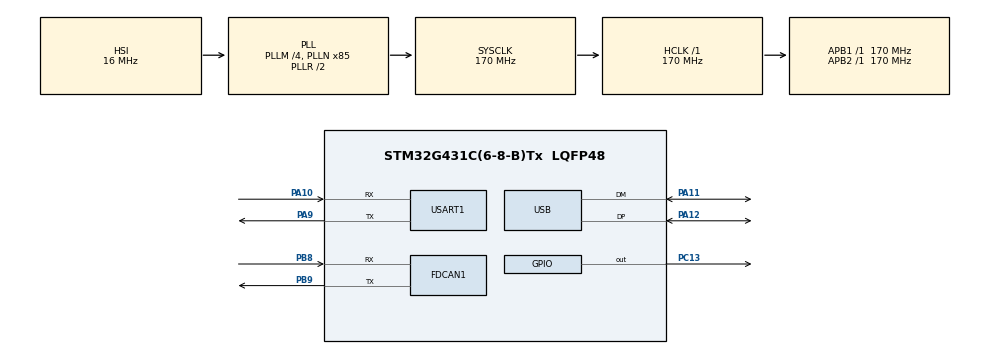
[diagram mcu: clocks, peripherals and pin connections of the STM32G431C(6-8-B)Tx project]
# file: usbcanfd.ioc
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FDCAN1.CalculateBaudRateNominal=499999
FDCAN1.CalculateTimeBitNominal=2000
FDCAN1.CalculateTimeQuantumNominal=117.64705882352942
FDCAN1.DataPrescaler=5
FDCAN1.DataTimeSeg1=14
FDCAN1.DataTimeSeg2=2
FDCAN1.FrameFormat=FDCAN_FRAME_FD_BRS
FDCAN1.NominalPrescaler=20
FDCAN1.NominalTimeSeg1=14
FDCAN1.NominalTimeSeg2=2
Mcu.Family=STM32G4
Mcu.Name=STM32G431C(6-8-B)Tx
Mcu.Package=LQFP48
NVIC.FDCAN1_IT0_IRQn=true\:0\:0\:false\:false\:true\:true\:true\:true
NVIC.FDCAN1_IT1_IRQn=true\:0\:0\:false\:false\:true\:true\:true\:true
NVIC.PriorityGroup=NVIC_PRIORITYGROUP_4
NVIC.USB_LP_IRQn=true\:0\:0\:false\:false\:true\:false\:true\:true
PA10.Mode=Asynchronous
PA10.Signal=USART1_RX
PA11.Mode=Device
PA11.Signal=USB_DM
PA12.Mode=Device
PA12.Signal=USB_DP
PA9.Mode=Asynchronous
PA9.Signal=USART1_TX
PB8-BOOT0.Mode=FDCAN_Activate
PB8-BOOT0.Signal=FDCAN1_RX
PB9.Mode=FDCAN_Activate
PB9.Signal=FDCAN1_TX
PC13.PinState=GPIO_PIN_SET
PC13.Signal=GPIO_Output
PF0-OSC_IN.Mode=HSE-External-Oscillator
PF0-OSC_IN.Signal=RCC_OSC_IN
PF1-OSC_OUT.Mode=HSE-External-Oscillator
PF1-OSC_OUT.Signal=RCC_OSC_OUT
ProjectManager.HeapSize=0x200
ProjectManager.StackSize=0x400
ProjectManager.TargetToolchain=STM32CubeIDE
RCC.ADC12Freq_Value=170000000
RCC.AHBFreq_Value=170000000
RCC.APB1Freq_Value=170000000
RCC.APB1TimFreq_Value=170000000
RCC.APB2Freq_Value=170000000
RCC.APB2TimFreq_Value=170000000
RCC.CK48CLockSelection=RCC_USBCLKSOURCE_HSI48
RCC.CortexFreq_Value=170000000
RCC.EXTERNAL_CLOCK_VALUE=12288000
RCC.HCLKFreq_Value=170000000
RCC.HSE_VALUE=8000000
RCC.HSI48_VALUE=48000000
RCC.HSI_VALUE=16000000
RCC.LSE_VALUE=32768
RCC.PLLM=RCC_PLLM_DIV4
RCC.PLLN=85
RCC.SYSCLKFreq_VALUE=170000000
RCC.SYSCLKSource=RCC_SYSCLKSOURCE_PLLCLK
RCC.USART1CLockSelection=RCC_USART1CLKSOURCE_HSI
RCC.USBFreq_Value=48000000
RCC.VCOOutputFreq_Value=340000000
USART1.VirtualMode-Asynchronous=VM_ASYNC
USB_DEVICE.CLASS_NAME_FS=CDC
USB_DEVICE.VirtualMode=Cdc
USB_DEVICE.VirtualModeFS=Cdc_FS
VP_SYS_VS_DBSignals.Mode=DisableDeadBatterySignals
VP_USB_DEVICE_VS_USB_DEVICE_CDC_FS.Mode=CDC_FS
board=custom

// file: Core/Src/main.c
/* USER CODE BEGIN Header */
/**
  ******************************************************************************
  * @file           : main.c
  * @brief          : Main program body
  ******************************************************************************
  * @attention
  *
  * Copyright (c) 2025 STMicroelectronics.
  * All rights reserved.
  *
  * This software is licensed under terms that can be found in the LICENSE file
  * in the root directory of this software component.
  * If no LICENSE file comes with this software, it is provided AS-IS.
  *
  ******************************************************************************
  */
/* USER CODE END Header */
#include "main.h"
#include "usb_device.h"

/* USER CODE BEGIN Includes */
#include "log.h"
#include "hsl.h"
#include "can.h"
/* USER CODE END Includes */

FDCAN_HandleTypeDef hfdcan1;

UART_HandleTypeDef huart1;

void SystemClock_Config(void);
static void MX_GPIO_Init(void);
static void MX_FDCAN1_Init(void);
static void MX_USART1_UART_Init(void);

int main(void)
{

  /* MCU Configuration--------------------------------------------------------*/

  /* Reset of all peripherals, Initializes the Flash interface and the Systick. */
  HAL_Init();

  /* Configure the system clock */
  SystemClock_Config();

  /* Initialize all configured peripherals */
  MX_GPIO_Init();
  MX_FDCAN1_Init();
  MX_USART1_UART_Init();
  MX_USB_Device_Init();
  /* USER CODE BEGIN 2 */

  log_init();
  hsl_init();

  /* USER CODE END 2 */

  /* Infinite loop */
  /* USER CODE BEGIN WHILE */
  while (1)
  {
    log_process();
    hsl_process();
    can_process();
    /* USER CODE END WHILE */

  }
}

void SystemClock_Config(void)
{
  RCC_OscInitTypeDef RCC_OscInitStruct = {0};
  RCC_ClkInitTypeDef RCC_ClkInitStruct = {0};

  /** Configure the main internal regulator output voltage
  */
  HAL_PWREx_ControlVoltageScaling(PWR_REGULATOR_VOLTAGE_SCALE1_BOOST);

  /** Initializes the RCC Oscillators according to the specified parameters
  * in the RCC_OscInitTypeDef structure.
  */
  RCC_OscInitStruct.OscillatorType = RCC_OSCILLATORTYPE_HSI|RCC_OSCILLATORTYPE_HSI48;
  RCC_OscInitStruct.HSIState = RCC_HSI_ON;
  RCC_OscInitStruct.HSICalibrationValue = RCC_HSICALIBRATION_DEFAULT;
  RCC_OscInitStruct.HSI48State = RCC_HSI48_ON;
  RCC_OscInitStruct.PLL.PLLState = RCC_PLL_ON;
  RCC_OscInitStruct.PLL.PLLSource = RCC_PLLSOURCE_HSI;
  RCC_OscInitStruct.PLL.PLLM = RCC_PLLM_DIV4;
  RCC_OscInitStruct.PLL.PLLN = 85;
  RCC_OscInitStruct.PLL.PLLP = RCC_PLLP_DIV2;
  RCC_OscInitStruct.PLL.PLLQ = RCC_PLLQ_DIV2;
  RCC_OscInitStruct.PLL.PLLR = RCC_PLLR_DIV2;
  if (HAL_RCC_OscConfig(&RCC_OscInitStruct) != HAL_OK)
  {
    Error_Handler();
  }

  /** Initializes the CPU, AHB and APB buses clocks
  */
  RCC_ClkInitStruct.ClockType = RCC_CLOCKTYPE_HCLK|RCC_CLOCKTYPE_SYSCLK
                              |RCC_CLOCKTYPE_PCLK1|RCC_CLOCKTYPE_PCLK2;
  RCC_ClkInitStruct.SYSCLKSource = RCC_SYSCLKSOURCE_PLLCLK;
  RCC_ClkInitStruct.AHBCLKDivider = RCC_SYSCLK_DIV1;
  RCC_ClkInitStruct.APB1CLKDivider = RCC_HCLK_DIV1;
  RCC_ClkInitStruct.APB2CLKDivider = RCC_HCLK_DIV1;

  if (HAL_RCC_ClockConfig(&RCC_ClkInitStruct, FLASH_LATENCY_4) != HAL_OK)
  {
    Error_Handler();
  }
}

static void MX_FDCAN1_Init(void)
{

  hfdcan1.Instance = FDCAN1;
  hfdcan1.Init.ClockDivider = FDCAN_CLOCK_DIV1;
  hfdcan1.Init.FrameFormat = FDCAN_FRAME_FD_BRS;
  hfdcan1.Init.Mode = FDCAN_MODE_NORMAL;
  hfdcan1.Init.AutoRetransmission = DISABLE;
  hfdcan1.Init.TransmitPause = DISABLE;
  hfdcan1.Init.ProtocolException = DISABLE;
  hfdcan1.Init.NominalPrescaler = 20;
  hfdcan1.Init.NominalSyncJumpWidth = 1;
  hfdcan1.Init.NominalTimeSeg1 = 14;
  hfdcan1.Init.NominalTimeSeg2 = 2;
  hfdcan1.Init.DataPrescaler = 5;
  hfdcan1.Init.DataSyncJumpWidth = 1;
  hfdcan1.Init.DataTimeSeg1 = 14;
  hfdcan1.Init.DataTimeSeg2 = 2;
  hfdcan1.Init.StdFiltersNbr = 0;
  hfdcan1.Init.ExtFiltersNbr = 0;
  hfdcan1.Init.TxFifoQueueMode = FDCAN_TX_FIFO_OPERATION;
  if (HAL_FDCAN_Init(&hfdcan1) != HAL_OK)
  {
    Error_Handler();
  }

}

static void MX_USART1_UART_Init(void)
{

  huart1.Instance = USART1;
  huart1.Init.BaudRate = 115200;
  huart1.Init.WordLength = UART_WORDLENGTH_8B;
  huart1.Init.StopBits = UART_STOPBITS_1;
  huart1.Init.Parity = UART_PARITY_NONE;
  huart1.Init.Mode = UART_MODE_TX_RX;
  huart1.Init.HwFlowCtl = UART_HWCONTROL_NONE;
  huart1.Init.OverSampling = UART_OVERSAMPLING_16;
  huart1.Init.OneBitSampling = UART_ONE_BIT_SAMPLE_DISABLE;
  huart1.Init.ClockPrescaler = UART_PRESCALER_DIV1;
  huart1.AdvancedInit.AdvFeatureInit = UART_ADVFEATURE_NO_INIT;
  if (HAL_UART_Init(&huart1) != HAL_OK)
  {
    Error_Handler();
  }
  if (HAL_UARTEx_SetTxFifoThreshold(&huart1, UART_TXFIFO_THRESHOLD_1_8) != HAL_OK)
  {
    Error_Handler();
  }
  if (HAL_UARTEx_SetRxFifoThreshold(&huart1, UART_RXFIFO_THRESHOLD_1_8) != HAL_OK)
  {
    Error_Handler();
  }
  if (HAL_UARTEx_DisableFifoMode(&huart1) != HAL_OK)
  {
    Error_Handler();
  }

}

static void MX_GPIO_Init(void)
{
  GPIO_InitTypeDef GPIO_InitStruct = {0};

  /* GPIO Ports Clock Enable */
  __HAL_RCC_GPIOC_CLK_ENABLE();
  __HAL_RCC_GPIOF_CLK_ENABLE();
  __HAL_RCC_GPIOA_CLK_ENABLE();
  __HAL_RCC_GPIOB_CLK_ENABLE();

  /*Configure GPIO pin Output Level */
  HAL_GPIO_WritePin(GPIOC, GPIO_PIN_13, GPIO_PIN_SET);

  /*Configure GPIO pin : PC13 */
  GPIO_InitStruct.Pin = GPIO_PIN_13;
  GPIO_InitStruct.Mode = GPIO_MODE_OUTPUT_PP;
  GPIO_InitStruct.Pull = GPIO_NOPULL;
  GPIO_InitStruct.Speed = GPIO_SPEED_FREQ_LOW;
  HAL_GPIO_Init(GPIOC, &GPIO_InitStruct);

}

void Error_Handler(void)
{
  __disable_irq();
  while (1)
  {
  }
}
